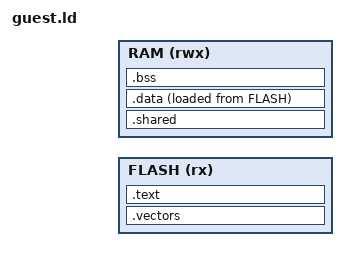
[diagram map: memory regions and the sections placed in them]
/* guest.ld
 *
 * Copyright (C) 2026 wolfSSL Inc.
 *
 * This file is part of wolfTrust.
 *
 * wolfTrust is free software; you can redistribute it and/or modify
 * it under the terms of the GNU General Public License as published by
 * the Free Software Foundation; either version 3 of the License, or
 * (at your option) any later version.
 *
 * wolfTrust is distributed in the hope that it will be useful,
 * but WITHOUT ANY WARRANTY; without even the implied warranty of
 * MERCHANTABILITY or FITNESS FOR A PARTICULAR PURPOSE.  See the
 * GNU General Public License for more details.
 *
 * You should have received a copy of the GNU General Public License
 * along with this program; if not, see <https://www.gnu.org/licenses/>.
 */

ENTRY(Reset_Handler)

MEMORY {
  FLASH (rx) : ORIGIN = GUEST_FLASH_ORIGIN, LENGTH = GUEST_FLASH_LENGTH
  RAM   (rwx): ORIGIN = GUEST_RAM_ORIGIN, LENGTH = GUEST_RAM_LENGTH
}

/* The top 32 bytes are the conformance NSPE MMIO window (pal_config.h). */
_estack = ORIGIN(RAM) + LENGTH(RAM) - 0x20;

SECTIONS {
  .shared ORIGIN(RAM) (NOLOAD) : {
    *(.shared*)
  } > RAM

  .vectors GUEST_FLASH_ORIGIN : {
    KEEP(*(.vectors))
  } > FLASH

  .text : {
    *(.text*)
    *(.rodata*)
  } > FLASH

  .data : {
    _sdata = .;
    *(.data*)
    _edata = .;
  } > RAM AT > FLASH
  _sidata = LOADADDR(.data);

  .bss (NOLOAD) : {
    _sbss = .;
    *(.bss*)
    *(COMMON)
    _ebss = .;
  } > RAM
}
